AUTOSAR XML (schema 314)
package /ComponentType
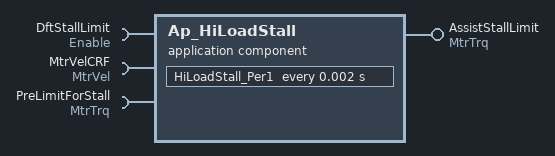
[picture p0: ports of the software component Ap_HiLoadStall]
  application software component type Ap_HiLoadStall
    provide port AssistStallLimit: unqueued-sender-com-spec{data-element=MtrNm_f32, can-invalidate=false, init-value=D_MTRTRQCMDHILMT_MTRNM_F32}, provided-interface=MtrTrq
    require port DftStallLimit: unqueued-receiver-com-spec{data-element=Cnt_lgc, init-value=D_FALSE_CNT_LGC}, required-interface=Enable
    require port MtrVelCRF: unqueued-receiver-com-spec{data-element=MtrRadpS_f32, init-value=D_ZERO_ULS_F32}, required-interface=MtrVel
    require port PreLimitForStall: unqueued-receiver-com-spec{data-element=MtrNm_f32, init-value=D_ZERO_ULS_F32}, required-interface=MtrTrq
  internal behavior Ap_HiLoadStall_InternalBehavior: component=Ap_HiLoadStall
    timing event TMT_HiLoadStall_Per1: start-on-event=HiLoadStall_Per1, period=0.002
    port-api-options:
      enable-take-address=false, indirect-api=false, port=AssistStallLimit
      enable-take-address=false, indirect-api=false, port=DftStallLimit
      enable-take-address=false, indirect-api=false, port=MtrVelCRF
      enable-take-address=false, indirect-api=false, port=PreLimitForStall
    runnable HiLoadStall_Per1
      data read access READ_DftStallLimit_Cnt_lgc: data-element=DftStallLimit.Cnt_lgc
      data read access READ_MtrVelCRF_MtrRadpS_f32: data-element=MtrVelCRF.MtrRadpS_f32
      data read access READ_PreLimitForStall_MtrNm_f32: data-element=PreLimitForStall.MtrNm_f32
      data write access WRITE_AssistStallLimit_MtrNm_f32: data-element=AssistStallLimit.MtrNm_f32
  swc implementation Ap_HiLoadStall_Implementation: behavior=Ap_HiLoadStall_InternalBehavior
    code-descriptors:
      code Code: type=SRC
